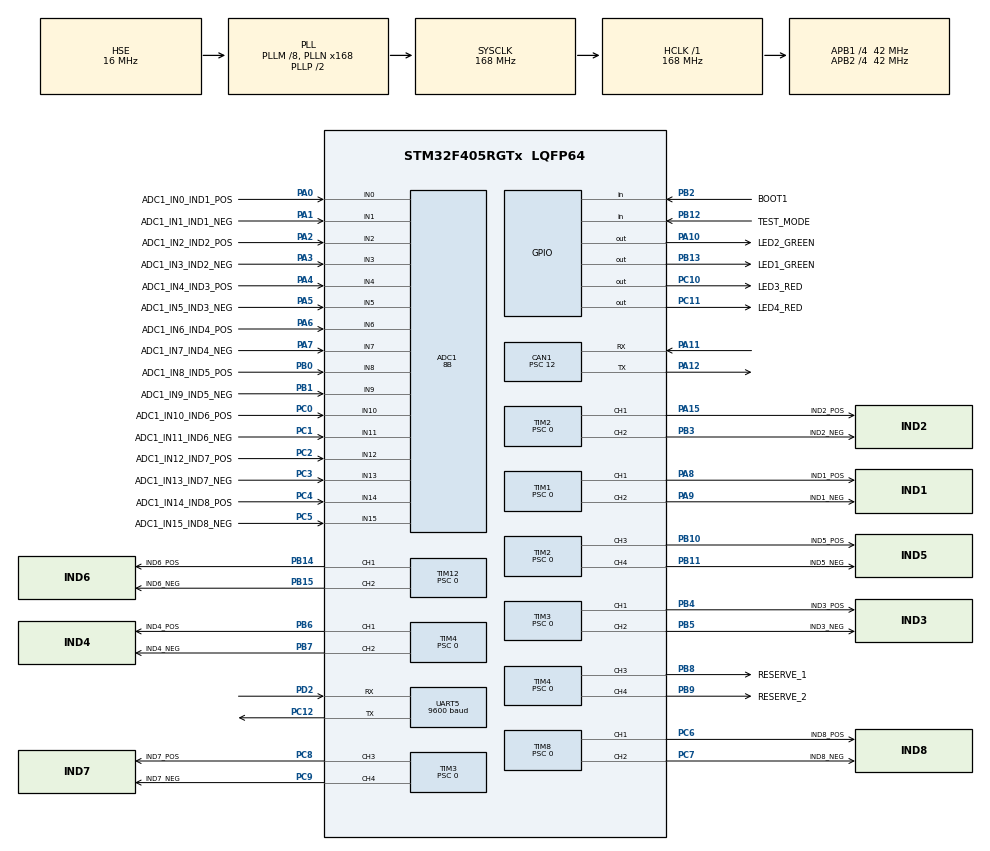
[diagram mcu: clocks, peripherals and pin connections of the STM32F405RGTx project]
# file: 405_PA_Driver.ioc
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ADC1.Channel-0\#ChannelRegularConversion=ADC_CHANNEL_4
ADC1.NbrOfConversionFlag=1
ADC1.Rank-0\#ChannelRegularConversion=1
ADC1.Resolution=ADC_RESOLUTION_8B
ADC1.SamplingTime-0\#ChannelRegularConversion=ADC_SAMPLETIME_3CYCLES
ADC1.master=1
CAN1.ABOM=ENABLE
CAN1.AWUM=DISABLE
CAN1.BS1=CAN_BS1_11TQ
CAN1.BS2=CAN_BS2_2TQ
CAN1.CalculateBaudRate=250000
CAN1.CalculateTimeBit=4000
CAN1.CalculateTimeQuantum=285.7142857142857
CAN1.NART=ENABLE
CAN1.Prescaler=12
CAN1.RFLM=ENABLE
CAN1.SJW=CAN_SJW_1TQ
CAN1.TXFP=ENABLE
Dma.Request0=TIM1_CH1
Dma.Request1=TIM1_CH2
Dma.Request2=TIM2_CH1
Dma.Request3=TIM2_CH2/CH4
Dma.Request4=TIM3_CH3
Dma.Request5=TIM3_CH4/UP
Dma.Request6=TIM4_CH1
Dma.Request7=TIM4_CH2
Dma.TIM1_CH1.0.Direction=DMA_MEMORY_TO_PERIPH
Dma.TIM1_CH1.0.FIFOMode=DMA_FIFOMODE_DISABLE
Dma.TIM1_CH1.0.Instance=DMA2_Stream1
Dma.TIM1_CH1.0.MemDataAlignment=DMA_MDATAALIGN_HALFWORD
Dma.TIM1_CH1.0.MemInc=DMA_MINC_ENABLE
Dma.TIM1_CH1.0.Mode=DMA_CIRCULAR
Dma.TIM1_CH1.0.PeriphDataAlignment=DMA_PDATAALIGN_HALFWORD
Dma.TIM1_CH1.0.PeriphInc=DMA_PINC_DISABLE
Dma.TIM1_CH1.0.Priority=DMA_PRIORITY_LOW
Dma.TIM1_CH2.1.Direction=DMA_MEMORY_TO_PERIPH
Dma.TIM1_CH2.1.FIFOMode=DMA_FIFOMODE_DISABLE
Dma.TIM1_CH2.1.Instance=DMA2_Stream2
Dma.TIM1_CH2.1.MemDataAlignment=DMA_MDATAALIGN_HALFWORD
Dma.TIM1_CH2.1.MemInc=DMA_MINC_ENABLE
Dma.TIM1_CH2.1.Mode=DMA_CIRCULAR
Dma.TIM1_CH2.1.PeriphDataAlignment=DMA_PDATAALIGN_HALFWORD
Dma.TIM1_CH2.1.PeriphInc=DMA_PINC_DISABLE
Dma.TIM1_CH2.1.Priority=DMA_PRIORITY_LOW
Dma.TIM2_CH1.2.Direction=DMA_MEMORY_TO_PERIPH
Dma.TIM2_CH1.2.FIFOMode=DMA_FIFOMODE_DISABLE
Dma.TIM2_CH1.2.Instance=DMA1_Stream5
Dma.TIM2_CH1.2.MemDataAlignment=DMA_MDATAALIGN_HALFWORD
Dma.TIM2_CH1.2.MemInc=DMA_MINC_ENABLE
Dma.TIM2_CH1.2.Mode=DMA_CIRCULAR
Dma.TIM2_CH1.2.PeriphDataAlignment=DMA_PDATAALIGN_HALFWORD
Dma.TIM2_CH1.2.PeriphInc=DMA_PINC_DISABLE
Dma.TIM2_CH1.2.Priority=DMA_PRIORITY_LOW
Dma.TIM2_CH2/CH4.3.Direction=DMA_MEMORY_TO_PERIPH
Dma.TIM2_CH2/CH4.3.FIFOMode=DMA_FIFOMODE_DISABLE
Dma.TIM2_CH2/CH4.3.Instance=DMA1_Stream6
Dma.TIM2_CH2/CH4.3.MemDataAlignment=DMA_MDATAALIGN_HALFWORD
Dma.TIM2_CH2/CH4.3.MemInc=DMA_MINC_ENABLE
Dma.TIM2_CH2/CH4.3.Mode=DMA_CIRCULAR
Dma.TIM2_CH2/CH4.3.PeriphDataAlignment=DMA_PDATAALIGN_HALFWORD
Dma.TIM2_CH2/CH4.3.PeriphInc=DMA_PINC_DISABLE
Dma.TIM2_CH2/CH4.3.Priority=DMA_PRIORITY_LOW
Dma.TIM3_CH3.4.Direction=DMA_MEMORY_TO_PERIPH
Dma.TIM3_CH3.4.FIFOMode=DMA_FIFOMODE_DISABLE
Dma.TIM3_CH3.4.Instance=DMA1_Stream7
Dma.TIM3_CH3.4.MemDataAlignment=DMA_MDATAALIGN_HALFWORD
Dma.TIM3_CH3.4.MemInc=DMA_MINC_ENABLE
Dma.TIM3_CH3.4.Mode=DMA_CIRCULAR
Dma.TIM3_CH3.4.PeriphDataAlignment=DMA_PDATAALIGN_HALFWORD
Dma.TIM3_CH3.4.PeriphInc=DMA_PINC_DISABLE
Dma.TIM3_CH3.4.Priority=DMA_PRIORITY_LOW
Dma.TIM3_CH4/UP.5.Direction=DMA_MEMORY_TO_PERIPH
Dma.TIM3_CH4/UP.5.FIFOMode=DMA_FIFOMODE_DISABLE
Dma.TIM3_CH4/UP.5.Instance=DMA1_Stream2
Dma.TIM3_CH4/UP.5.MemDataAlignment=DMA_MDATAALIGN_HALFWORD
Dma.TIM3_CH4/UP.5.MemInc=DMA_MINC_ENABLE
Dma.TIM3_CH4/UP.5.Mode=DMA_CIRCULAR
Dma.TIM3_CH4/UP.5.PeriphDataAlignment=DMA_PDATAALIGN_HALFWORD
Dma.TIM3_CH4/UP.5.PeriphInc=DMA_PINC_DISABLE
Dma.TIM3_CH4/UP.5.Priority=DMA_PRIORITY_LOW
Dma.TIM4_CH1.6.Direction=DMA_MEMORY_TO_PERIPH
Dma.TIM4_CH1.6.FIFOMode=DMA_FIFOMODE_DISABLE
Dma.TIM4_CH1.6.Instance=DMA1_Stream0
Dma.TIM4_CH1.6.MemDataAlignment=DMA_MDATAALIGN_HALFWORD
Dma.TIM4_CH1.6.MemInc=DMA_MINC_ENABLE
Dma.TIM4_CH1.6.Mode=DMA_CIRCULAR
Dma.TIM4_CH1.6.PeriphDataAlignment=DMA_PDATAALIGN_HALFWORD
Dma.TIM4_CH1.6.PeriphInc=DMA_PINC_DISABLE
Dma.TIM4_CH1.6.Priority=DMA_PRIORITY_LOW
Dma.TIM4_CH2.7.Direction=DMA_MEMORY_TO_PERIPH
Dma.TIM4_CH2.7.FIFOMode=DMA_FIFOMODE_DISABLE
Dma.TIM4_CH2.7.Instance=DMA1_Stream3
Dma.TIM4_CH2.7.MemDataAlignment=DMA_MDATAALIGN_HALFWORD
Dma.TIM4_CH2.7.MemInc=DMA_MINC_ENABLE
Dma.TIM4_CH2.7.Mode=DMA_CIRCULAR
Dma.TIM4_CH2.7.PeriphDataAlignment=DMA_PDATAALIGN_HALFWORD
Dma.TIM4_CH2.7.PeriphInc=DMA_PINC_DISABLE
Dma.TIM4_CH2.7.Priority=DMA_PRIORITY_LOW
FREERTOS.CountingSemaphores01=GeneratePWMSemaphore,30,Dynamic,NULL
FREERTOS.Mutexes01=MutexChangeParams,Dynamic,NULL
FREERTOS.Queues01=SignalGeneratorQueue,8,tdPwmData,0,Dynamic,NULL,NULL
FREERTOS.Tasks01=defaultTask,24,128,StartDefaultTask,As weak,NULL,Dynamic,NULL,NULL;GenHalfwave,24,128,GenerateHalfwaveTask,As weak,NULL,Dynamic,NULL,NULL;ChngSignalParam,40,128,ChangeSignalParamsTask,As weak,NULL,Dynamic,NULL,NULL;Gen_IT_wave,24,128,Generate_IT_wave,As weak,NULL,Dynamic,NULL,NULL
Mcu.Family=STM32F4
Mcu.Name=STM32F405RGTx
Mcu.Package=LQFP64
NVIC.ADC_IRQn=true\:5\:0\:true\:false\:true\:true\:true\:true
NVIC.CAN1_RX0_IRQn=true\:5\:0\:false\:false\:true\:true\:true\:true
NVIC.CAN1_RX1_IRQn=true\:5\:0\:false\:false\:true\:true\:true\:true
NVIC.CAN1_SCE_IRQn=true\:5\:0\:false\:false\:true\:true\:true\:true
NVIC.CAN1_TX_IRQn=true\:5\:0\:false\:false\:true\:true\:true\:true
NVIC.DMA1_Stream0_IRQn=true\:5\:0\:false\:false\:true\:true\:false\:true
NVIC.DMA1_Stream2_IRQn=true\:5\:0\:false\:false\:true\:true\:false\:true
NVIC.DMA1_Stream3_IRQn=true\:5\:0\:false\:false\:true\:true\:false\:true
NVIC.DMA1_Stream5_IRQn=true\:5\:0\:false\:false\:true\:true\:false\:true
NVIC.DMA1_Stream6_IRQn=true\:5\:0\:false\:false\:true\:true\:false\:true
NVIC.DMA1_Stream7_IRQn=true\:5\:0\:false\:false\:true\:true\:false\:true
NVIC.DMA2_Stream1_IRQn=true\:5\:0\:false\:false\:true\:true\:false\:true
NVIC.DMA2_Stream2_IRQn=true\:5\:0\:false\:false\:true\:true\:false\:true
NVIC.PriorityGroup=NVIC_PRIORITYGROUP_4
NVIC.TIM5_IRQn=true\:5\:0\:false\:false\:true\:true\:true\:true
NVIC.TIM6_DAC_IRQn=true\:15\:0\:false\:false\:true\:false\:false\:true
NVIC.TIM7_IRQn=true\:5\:0\:false\:false\:true\:true\:true\:true
NVIC.TimeBase=TIM6_DAC_IRQn
NVIC.TimeBaseIP=TIM6
NVIC.UART5_IRQn=true\:5\:0\:false\:false\:true\:true\:true\:true
PA0-WKUP.GPIO_Label=ADC1_IN0_IND1_POS
PA0-WKUP.Signal=ADCx_IN0
PA1.GPIO_Label=ADC1_IN1_IND1_NEG
PA1.Signal=ADCx_IN1
PA10.GPIO_Label=LED2_GREEN
PA10.Signal=GPIO_Output
PA11.Mode=CAN_Activate
PA11.Signal=CAN1_RX
PA12.Mode=CAN_Activate
PA12.Signal=CAN1_TX
PA13.Mode=Serial_Wire
PA13.Signal=SYS_JTMS-SWDIO
PA14.Mode=Serial_Wire
PA14.Signal=SYS_JTCK-SWCLK
PA15.GPIO_Label=IND2_POS
PA15.GPIO_PuPd=GPIO_NOPULL
PA15.GPIO_Speed=GPIO_SPEED_FREQ_HIGH
PA15.Signal=S_TIM2_CH1_ETR
PA2.GPIO_Label=ADC1_IN2_IND2_POS
PA2.Signal=ADCx_IN2
PA3.GPIO_Label=ADC1_IN3_IND2_NEG
PA3.Signal=ADCx_IN3
PA4.GPIO_Label=ADC1_IN4_IND3_POS
PA4.Signal=ADCx_IN4
PA5.GPIO_Label=ADC1_IN5_IND3_NEG
PA5.Signal=ADCx_IN5
PA6.GPIO_Label=ADC1_IN6_IND4_POS
PA6.Signal=ADCx_IN6
PA7.GPIO_Label=ADC1_IN7_IND4_NEG
PA7.Signal=ADCx_IN7
PA8.GPIO_Label=IND1_POS
PA8.GPIO_PuPd=GPIO_NOPULL
PA8.GPIO_Speed=GPIO_SPEED_FREQ_HIGH
PA8.Signal=S_TIM1_CH1
PA9.GPIO_Label=IND1_NEG
PA9.GPIO_PuPd=GPIO_NOPULL
PA9.GPIO_Speed=GPIO_SPEED_FREQ_HIGH
PA9.Signal=S_TIM1_CH2
PB0.GPIO_Label=ADC1_IN8_IND5_POS
PB0.Signal=ADCx_IN8
PB1.GPIO_Label=ADC1_IN9_IND5_NEG
PB1.Signal=ADCx_IN9
PB10.GPIO_Label=IND5_POS
PB10.GPIO_PuPd=GPIO_NOPULL
PB10.GPIO_Speed=GPIO_SPEED_FREQ_HIGH
PB10.Signal=S_TIM2_CH3
PB11.GPIO_Label=IND5_NEG
PB11.GPIO_PuPd=GPIO_NOPULL
PB11.GPIO_Speed=GPIO_SPEED_FREQ_HIGH
PB11.Signal=S_TIM2_CH4
PB12.GPIO_Label=TEST_MODE
PB12.Signal=GPIO_Input
PB13.GPIO_Label=LED1_GREEN
PB13.Signal=GPIO_Output
PB14.GPIO_Label=IND6_POS
PB14.GPIO_Speed=GPIO_SPEED_FREQ_HIGH
PB14.Signal=S_TIM12_CH1
PB15.GPIO_Label=IND6_NEG
PB15.GPIO_Speed=GPIO_SPEED_FREQ_HIGH
PB15.Signal=S_TIM12_CH2
PB2.GPIO_Label=BOOT1
PB2.Signal=GPIO_Input
PB3.GPIO_Label=IND2_NEG
PB3.GPIO_PuPd=GPIO_NOPULL
PB3.GPIO_Speed=GPIO_SPEED_FREQ_HIGH
PB3.Signal=S_TIM2_CH2
PB4.GPIO_Label=IND3_POS
PB4.GPIO_PuPd=GPIO_NOPULL
PB4.GPIO_Speed=GPIO_SPEED_FREQ_HIGH
PB4.Signal=S_TIM3_CH1
PB5.GPIO_Label=IND3_NEG
PB5.GPIO_PuPd=GPIO_NOPULL
PB5.GPIO_Speed=GPIO_SPEED_FREQ_HIGH
PB5.Signal=S_TIM3_CH2
PB6.GPIO_Label=IND4_POS
PB6.GPIO_Speed=GPIO_SPEED_FREQ_HIGH
PB6.Signal=S_TIM4_CH1
PB7.GPIO_Label=IND4_NEG
PB7.GPIO_Speed=GPIO_SPEED_FREQ_HIGH
PB7.Signal=S_TIM4_CH2
PB8.GPIO_Label=RESERVE_1
PB8.GPIO_Speed=GPIO_SPEED_FREQ_HIGH
PB8.Signal=S_TIM4_CH3
PB9.GPIO_Label=RESERVE_2
PB9.GPIO_Speed=GPIO_SPEED_FREQ_HIGH
PB9.Signal=S_TIM4_CH4
PC0.GPIO_Label=ADC1_IN10_IND6_POS
PC0.Signal=ADCx_IN10
PC1.GPIO_Label=ADC1_IN11_IND6_NEG
PC1.Signal=ADCx_IN11
PC10.GPIO_Label=LED3_RED
PC10.Signal=GPIO_Output
PC11.GPIO_Label=LED4_RED
PC11.Signal=GPIO_Output
PC12.Mode=Asynchronous
PC12.Signal=UART5_TX
PC2.GPIO_Label=ADC1_IN12_IND7_POS
PC2.Signal=ADCx_IN12
PC3.GPIO_Label=ADC1_IN13_IND7_NEG
PC3.Signal=ADCx_IN13
PC4.GPIO_Label=ADC1_IN14_IND8_POS
PC4.Signal=ADCx_IN14
PC5.GPIO_Label=ADC1_IN15_IND8_NEG
PC5.Signal=ADCx_IN15
PC6.GPIO_Label=IND8_POS
PC6.GPIO_Speed=GPIO_SPEED_FREQ_HIGH
PC6.Signal=S_TIM8_CH1
PC7.GPIO_Label=IND8_NEG
PC7.GPIO_Speed=GPIO_SPEED_FREQ_HIGH
PC7.Signal=S_TIM8_CH2
PC8.GPIO_Label=IND7_POS
PC8.GPIO_PuPd=GPIO_NOPULL
PC8.GPIO_Speed=GPIO_SPEED_FREQ_HIGH
PC8.Signal=S_TIM3_CH3
PC9.GPIO_Label=IND7_NEG
PC9.GPIO_PuPd=GPIO_NOPULL
PC9.GPIO_Speed=GPIO_SPEED_FREQ_HIGH
PC9.Signal=S_TIM3_CH4
PD2.Mode=Asynchronous
PD2.Signal=UART5_RX
PH0-OSC_IN.Mode=HSE-External-Oscillator
PH0-OSC_IN.Signal=RCC_OSC_IN
PH1-OSC_OUT.Mode=HSE-External-Oscillator
PH1-OSC_OUT.Signal=RCC_OSC_OUT
ProjectManager.HeapSize=0x2000
ProjectManager.StackSize=0x2000
ProjectManager.TargetToolchain=EWARM V8.32
RCC.48MHZClocksFreq_Value=84000000
RCC.AHBFreq_Value=168000000
RCC.APB1CLKDivider=RCC_HCLK_DIV4
RCC.APB1Freq_Value=42000000
RCC.APB1TimFreq_Value=84000000
RCC.APB2CLKDivider=RCC_HCLK_DIV4
RCC.APB2Freq_Value=42000000
RCC.APB2TimFreq_Value=84000000
RCC.CortexFreq_Value=168000000
RCC.HCLKFreq_Value=168000000
RCC.HSE_VALUE=16000000
RCC.HSI_VALUE=16000000
RCC.LSE_VALUE=32768
RCC.PLLM=8
RCC.PLLN=168
RCC.PLLSourceVirtual=RCC_PLLSOURCE_HSE
RCC.SYSCLKFreq_VALUE=168000000
RCC.SYSCLKSource=RCC_SYSCLKSOURCE_PLLCLK
RCC.VCOOutputFreq_Value=336000000
SH.ADCx_IN0.0=ADC1_IN0,IN0
SH.ADCx_IN1.0=ADC1_IN1,IN1
SH.ADCx_IN10.0=ADC1_IN10,IN10
SH.ADCx_IN11.0=ADC1_IN11,IN11
SH.ADCx_IN12.0=ADC1_IN12,IN12
SH.ADCx_IN13.0=ADC1_IN13,IN13
SH.ADCx_IN14.0=ADC1_IN14,IN14
SH.ADCx_IN15.0=ADC1_IN15,IN15
SH.ADCx_IN2.0=ADC1_IN2,IN2
SH.ADCx_IN3.0=ADC1_IN3,IN3
SH.ADCx_IN4.0=ADC1_IN4,IN4
SH.ADCx_IN5.0=ADC1_IN5,IN5
SH.ADCx_IN6.0=ADC1_IN6,IN6
SH.ADCx_IN7.0=ADC1_IN7,IN7
SH.ADCx_IN8.0=ADC1_IN8,IN8
SH.ADCx_IN9.0=ADC1_IN9,IN9
SH.S_TIM12_CH1.0=TIM12_CH1,PWM Generation1 CH1
SH.S_TIM12_CH2.0=TIM12_CH2,PWM Generation2 CH2
SH.S_TIM1_CH1.0=TIM1_CH1,PWM Generation1 CH1
SH.S_TIM1_CH2.0=TIM1_CH2,PWM Generation2 CH2
SH.S_TIM2_CH1_ETR.0=TIM2_CH1,PWM Generation1 CH1
SH.S_TIM2_CH2.0=TIM2_CH2,PWM Generation2 CH2
SH.S_TIM2_CH3.0=TIM2_CH3,PWM Generation3 CH3
SH.S_TIM2_CH4.0=TIM2_CH4,PWM Generation4 CH4
SH.S_TIM3_CH1.0=TIM3_CH1,PWM Generation1 CH1
SH.S_TIM3_CH2.0=TIM3_CH2,PWM Generation2 CH2
SH.S_TIM3_CH3.0=TIM3_CH3,PWM Generation3 CH3
SH.S_TIM3_CH4.0=TIM3_CH4,PWM Generation4 CH4
SH.S_TIM4_CH1.0=TIM4_CH1,PWM Generation1 CH1
SH.S_TIM4_CH2.0=TIM4_CH2,PWM Generation2 CH2
SH.S_TIM4_CH3.0=TIM4_CH3,PWM Generation3 CH3
SH.S_TIM4_CH4.0=TIM4_CH4,PWM Generation4 CH4
SH.S_TIM8_CH1.0=TIM8_CH1,PWM Generation1 CH1
SH.S_TIM8_CH2.0=TIM8_CH2,PWM Generation2 CH2
TIM1.AutoReloadPreload=TIM_AUTORELOAD_PRELOAD_ENABLE
TIM1.Channel-PWM\ Generation1\ CH1=TIM_CHANNEL_1
TIM1.Channel-PWM\ Generation2\ CH2=TIM_CHANNEL_2
TIM1.OC1Preload_PWM=ENABLE
TIM1.OC2Preload_PWM=ENABLE
TIM1.OCPolarity_1=TIM_OCPOLARITY_LOW
TIM1.OCPolarity_2=TIM_OCPOLARITY_LOW
TIM1.Period=656
TIM1.Prescaler=0
TIM1.Pulse-PWM\ Generation1\ CH1=0
TIM1.Pulse-PWM\ Generation2\ CH2=0
TIM12.Channel-PWM\ Generation1\ CH1=TIM_CHANNEL_1
TIM12.Channel-PWM\ Generation2\ CH2=TIM_CHANNEL_2
TIM12.OCPolarity_1=TIM_OCPOLARITY_LOW
TIM12.OCPolarity_2=TIM_OCPOLARITY_LOW
TIM12.Period=656
TIM12.Prescaler=0
TIM12.Pulse-PWM\ Generation1\ CH1=0
TIM12.Pulse-PWM\ Generation2\ CH2=0
TIM2.AutoReloadPreload=TIM_AUTORELOAD_PRELOAD_ENABLE
TIM2.Channel-PWM\ Generation1\ CH1=TIM_CHANNEL_1
TIM2.Channel-PWM\ Generation2\ CH2=TIM_CHANNEL_2
TIM2.Channel-PWM\ Generation3\ CH3=TIM_CHANNEL_3
TIM2.Channel-PWM\ Generation4\ CH4=TIM_CHANNEL_4
TIM2.OCPolarity_1=TIM_OCPOLARITY_LOW
TIM2.OCPolarity_2=TIM_OCPOLARITY_LOW
TIM2.OCPolarity_3=TIM_OCPOLARITY_LOW
TIM2.OCPolarity_4=TIM_OCPOLARITY_LOW
TIM2.Period=656
TIM2.Prescaler=0
TIM2.Pulse-PWM\ Generation1\ CH1=0
TIM2.Pulse-PWM\ Generation2\ CH2=0
TIM2.Pulse-PWM\ Generation3\ CH3=0
TIM2.Pulse-PWM\ Generation4\ CH4=0
TIM2.TIM_MasterOutputTrigger=TIM_TRGO_RESET
TIM3.AutoReloadPreload=TIM_AUTORELOAD_PRELOAD_ENABLE
TIM3.Channel-PWM\ Generation1\ CH1=TIM_CHANNEL_1
TIM3.Channel-PWM\ Generation2\ CH2=TIM_CHANNEL_2
TIM3.Channel-PWM\ Generation3\ CH3=TIM_CHANNEL_3
TIM3.Channel-PWM\ Generation4\ CH4=TIM_CHANNEL_4
TIM3.OCPolarity_1=TIM_OCPOLARITY_LOW
TIM3.OCPolarity_2=TIM_OCPOLARITY_LOW
TIM3.OCPolarity_3=TIM_OCPOLARITY_LOW
TIM3.OCPolarity_4=TIM_OCPOLARITY_LOW
TIM3.Period=656
TIM3.Prescaler=0
TIM3.Pulse-PWM\ Generation1\ CH1=0
TIM3.Pulse-PWM\ Generation2\ CH2=0
TIM3.Pulse-PWM\ Generation3\ CH3=0
TIM3.Pulse-PWM\ Generation4\ CH4=0
TIM4.AutoReloadPreload=TIM_AUTORELOAD_PRELOAD_ENABLE
TIM4.Channel-PWM\ Generation1\ CH1=TIM_CHANNEL_1
TIM4.Channel-PWM\ Generation2\ CH2=TIM_CHANNEL_2
TIM4.Channel-PWM\ Generation3\ CH3=TIM_CHANNEL_3
TIM4.Channel-PWM\ Generation4\ CH4=TIM_CHANNEL_4
TIM4.OCPolarity_1=TIM_OCPOLARITY_LOW
TIM4.OCPolarity_2=TIM_OCPOLARITY_LOW
TIM4.OCPolarity_3=TIM_OCPOLARITY_LOW
TIM4.OCPolarity_4=TIM_OCPOLARITY_LOW
TIM4.Period=656
TIM4.Prescaler=0
TIM4.Pulse-PWM\ Generation1\ CH1=0
TIM4.Pulse-PWM\ Generation2\ CH2=0
TIM4.Pulse-PWM\ Generation3\ CH3=0
TIM5.AutoReloadPreload=TIM_AUTORELOAD_PRELOAD_ENABLE
TIM5.Period=5999
TIM5.Prescaler=13999
TIM7.Period=600
TIM7.Prescaler=140
TIM8.Channel-PWM\ Generation1\ CH1=TIM_CHANNEL_1
TIM8.Channel-PWM\ Generation2\ CH2=TIM_CHANNEL_2
TIM8.OCPolarity_1=TIM_OCPOLARITY_LOW
TIM8.OCPolarity_2=TIM_OCPOLARITY_LOW
TIM8.Period=656
TIM8.Prescaler=0
TIM8.Pulse-PWM\ Generation1\ CH1=0
TIM8.Pulse-PWM\ Generation2\ CH2=0
UART5.BaudRate=9600
UART5.Mode=MODE_RX
UART5.OverSampling=UART_OVERSAMPLING_16
UART5.VirtualMode=Asynchronous
VP_CRC_VS_CRC.Mode=CRC_Activate
VP_FREERTOS_VS_CMSIS_V2.Mode=CMSIS_V2
VP_SYS_VS_tim6.Mode=TIM6
VP_TIM5_VS_ClockSourceINT.Mode=Internal
VP_TIM7_VS_ClockSourceINT.Mode=Enable_Timer
board=custom

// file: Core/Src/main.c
/* USER CODE BEGIN Header */
/**
  ******************************************************************************
  * @file           : main.c
  * @brief          : Main program body
  ******************************************************************************
  * @attention
  *
  * Copyright (c) 2022 STMicroelectronics.
  * All rights reserved.
  *
  * This software is licensed under terms that can be found in the LICENSE file
  * in the root directory of this software component.
  * If no LICENSE file comes with this software, it is provided AS-IS.
  *
  ******************************************************************************
  */
/* USER CODE END Header */
#include "main.h"
#include "cmsis_os.h"
#include "adc.h"
#include "can.h"
#include "crc.h"
#include "dma.h"
#include "tim.h"
#include "usart.h"
#include "gpio.h"

/* USER CODE BEGIN Includes */
//#include "App/interface.h"
/* USER CODE END Includes */

void SystemClock_Config(void);
void MX_FREERTOS_Init(void);
/* USER CODE BEGIN PFP */
void UartStart(void);
/* USER CODE END PFP */

int main(void)
{

  /* MCU Configuration--------------------------------------------------------*/

  /* Reset of all peripherals, Initializes the Flash interface and the Systick. */
  HAL_Init();

  /* Configure the system clock */
  SystemClock_Config();

  /* Initialize all configured peripherals */
  MX_GPIO_Init();
  MX_DMA_Init();
  MX_ADC1_Init();
  MX_TIM1_Init();
  MX_TIM2_Init();
  MX_TIM3_Init();
  MX_TIM4_Init();
  MX_TIM8_Init();
  MX_TIM12_Init();
  MX_CAN1_Init();
  MX_CRC_Init();
  MX_TIM5_Init();
  MX_TIM7_Init();
  MX_UART5_Init();
  /* USER CODE BEGIN 2 */
  InitPwmControllers();
  UartStart();
  /* USER CODE END 2 */

  /* Init scheduler */
  osKernelInitialize();  /* Call init function for freertos objects (in freertos.c) */
  MX_FREERTOS_Init();
  /* Start scheduler */
  osKernelStart();

  /* We should never get here as control is now taken by the scheduler */
  /* Infinite loop */
  while (1)
  {

  }
}

void SystemClock_Config(void)
{
  RCC_OscInitTypeDef RCC_OscInitStruct = {0};
  RCC_ClkInitTypeDef RCC_ClkInitStruct = {0};

  /** Configure the main internal regulator output voltage
  */
  __HAL_RCC_PWR_CLK_ENABLE();
  __HAL_PWR_VOLTAGESCALING_CONFIG(PWR_REGULATOR_VOLTAGE_SCALE1);
  /** Initializes the RCC Oscillators according to the specified parameters
  * in the RCC_OscInitTypeDef structure.
  */
  RCC_OscInitStruct.OscillatorType = RCC_OSCILLATORTYPE_HSE;
  RCC_OscInitStruct.HSEState = RCC_HSE_ON;
  RCC_OscInitStruct.PLL.PLLState = RCC_PLL_ON;
  RCC_OscInitStruct.PLL.PLLSource = RCC_PLLSOURCE_HSE;
  RCC_OscInitStruct.PLL.PLLM = 8;
  RCC_OscInitStruct.PLL.PLLN = 168;
  RCC_OscInitStruct.PLL.PLLP = RCC_PLLP_DIV2;
  RCC_OscInitStruct.PLL.PLLQ = 4;
  if (HAL_RCC_OscConfig(&RCC_OscInitStruct) != HAL_OK)
  {
    Error_Handler();
  }
  /** Initializes the CPU, AHB and APB buses clocks
  */
  RCC_ClkInitStruct.ClockType = RCC_CLOCKTYPE_HCLK|RCC_CLOCKTYPE_SYSCLK
                              |RCC_CLOCKTYPE_PCLK1|RCC_CLOCKTYPE_PCLK2;
  RCC_ClkInitStruct.SYSCLKSource = RCC_SYSCLKSOURCE_PLLCLK;
  RCC_ClkInitStruct.AHBCLKDivider = RCC_SYSCLK_DIV1;
  RCC_ClkInitStruct.APB1CLKDivider = RCC_HCLK_DIV4;
  RCC_ClkInitStruct.APB2CLKDivider = RCC_HCLK_DIV4;

  if (HAL_RCC_ClockConfig(&RCC_ClkInitStruct, FLASH_LATENCY_5) != HAL_OK)
  {
    Error_Handler();
  }
}

void HAL_TIM_PeriodElapsedCallback(TIM_HandleTypeDef *htim)
{
  if (htim->Instance == TIM6) {
    HAL_IncTick();
  }
}

void Error_Handler(void)
{
  __disable_irq();
  while (1)
  {
  }
}

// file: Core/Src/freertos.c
/* USER CODE BEGIN Header */
/**
  ******************************************************************************
  * File Name          : freertos.c
  * Description        : Code for freertos applications
  ******************************************************************************
  * @attention
  *
  * Copyright (c) 2022 STMicroelectronics.
  * All rights reserved.
  *
  * This software is licensed under terms that can be found in the LICENSE file
  * in the root directory of this software component.
  * If no LICENSE file comes with this software, it is provided AS-IS.
  *
  ******************************************************************************
  */
/* USER CODE END Header */

#include "FreeRTOS.h"
#include "task.h"
#include "main.h"
#include "cmsis_os.h"

/* USER CODE BEGIN Includes */
#include "App/pwm_types.h"
/* USER CODE END Includes */

/* Definitions for defaultTask */
osThreadId_t defaultTaskHandle;
const osThreadAttr_t defaultTask_attributes = {
  .name = "defaultTask",
  .stack_size = 128 * 4,
  .priority = (osPriority_t) osPriorityNormal,
};
/* Definitions for GenHalfwave */
osThreadId_t GenHalfwaveHandle;
const osThreadAttr_t GenHalfwave_attributes = {
  .name = "GenHalfwave",
  .stack_size = 128 * 4,
  .priority = (osPriority_t) osPriorityNormal,
};
/* Definitions for ChngSignalParam */
osThreadId_t ChngSignalParamHandle;
const osThreadAttr_t ChngSignalParam_attributes = {
  .name = "ChngSignalParam",
  .stack_size = 128 * 4,
  .priority = (osPriority_t) osPriorityHigh,
};
/* Definitions for Gen_IT_wave */
osThreadId_t Gen_IT_waveHandle;
const osThreadAttr_t Gen_IT_wave_attributes = {
  .name = "Gen_IT_wave",
  .stack_size = 128 * 4,
  .priority = (osPriority_t) osPriorityNormal,
};
/* Definitions for SignalGeneratorQueue */
osMessageQueueId_t SignalGeneratorQueueHandle;
const osMessageQueueAttr_t SignalGeneratorQueue_attributes = {
  .name = "SignalGeneratorQueue"
};
/* Definitions for MutexChangeParams */
osMutexId_t MutexChangeParamsHandle;
const osMutexAttr_t MutexChangeParams_attributes = {
  .name = "MutexChangeParams"
};
/* Definitions for GeneratePWMSemaphore */
osSemaphoreId_t GeneratePWMSemaphoreHandle;
const osSemaphoreAttr_t GeneratePWMSemaphore_attributes = {
  .name = "GeneratePWMSemaphore"
};

void StartDefaultTask(void *argument);
void GenerateHalfwaveTask(void *argument);
void ChangeSignalParamsTask(void *argument);
void Generate_IT_wave(void *argument);

void MX_FREERTOS_Init(void); /* (MISRA C 2004 rule 8.1) */

void MX_FREERTOS_Init(void) {
  /* Create the mutex(es) */
  /* creation of MutexChangeParams */
  MutexChangeParamsHandle = osMutexNew(&MutexChangeParams_attributes);

  /* Create the semaphores(s) */
  /* creation of GeneratePWMSemaphore */
  GeneratePWMSemaphoreHandle = osSemaphoreNew(30, 30, &GeneratePWMSemaphore_attributes);

  /* Create the queue(s) */
  /* creation of SignalGeneratorQueue */
  SignalGeneratorQueueHandle = osMessageQueueNew (8, sizeof(tdPwmData), &SignalGeneratorQueue_attributes);

  /* Create the thread(s) */
  /* creation of defaultTask */
  defaultTaskHandle = osThreadNew(StartDefaultTask, NULL, &defaultTask_attributes);

  /* creation of GenHalfwave */
  GenHalfwaveHandle = osThreadNew(GenerateHalfwaveTask, NULL, &GenHalfwave_attributes);

  /* creation of ChngSignalParam */
  ChngSignalParamHandle = osThreadNew(ChangeSignalParamsTask, NULL, &ChngSignalParam_attributes);

  /* creation of Gen_IT_wave */
  Gen_IT_waveHandle = osThreadNew(Generate_IT_wave, NULL, &Gen_IT_wave_attributes);

}

__weak void StartDefaultTask(void *argument)
{
  for(;;)
  {
  }
}

__weak void GenerateHalfwaveTask(void *argument)
{
  for(;;)
  {
    osDelay(1);
  }
}

__weak void ChangeSignalParamsTask(void *argument)
{
  for(;;)
  {
    osDelay(1);
  }
}

__weak void Generate_IT_wave(void *argument)
{
  for(;;)
  {
    osDelay(1);
  }
}
